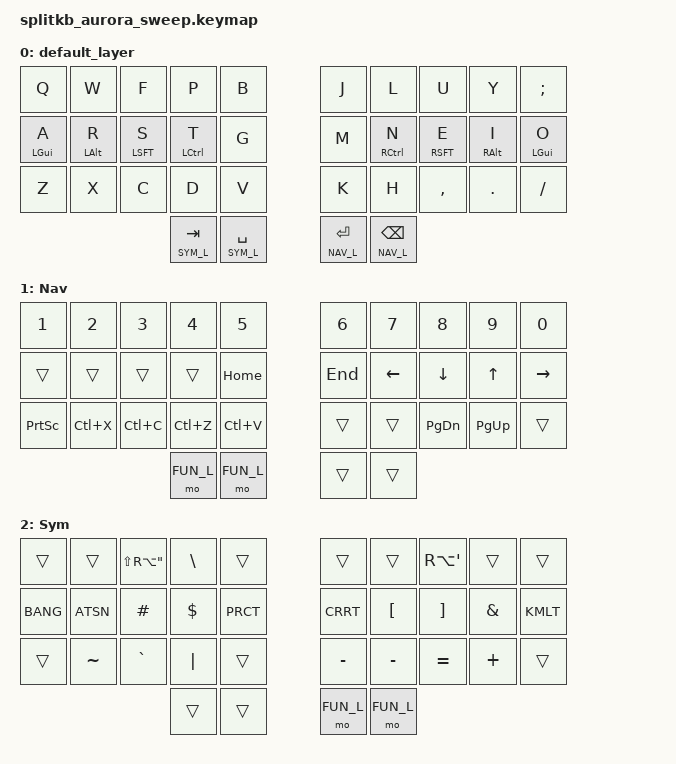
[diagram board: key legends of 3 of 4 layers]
/*
 * Copyright (c) 2022 The ZMK Contributors
 *
 * SPDX-License-Identifier: MIT
 */

#include <behaviors.dtsi>
#include <dt-bindings/zmk/keys.h>
#include <dt-bindings/zmk/bt.h>

#define DEF_L 0
#define NAV_L 1
#define SYM_L 2
#define FUN_L 3

// Using layer taps on thumbs, having quick tap as well helps w/ repeating space/backspace
&lt { quick_tap_ms = <200>; };


/ {
 behaviors {
        hm: homerow_mods {
            compatible = "zmk,behavior-hold-tap";
            #binding-cells = <2>;
            tapping_term_ms = <225>;
            flavor = "tap-preferred";
            bindings = <&kp>, <&kp>;
        };
    };

    macros {

        ZMK_MACRO(arrow,
            wait-ms = <30>;
            tap-ms = <40>;
            bindings = <&kp MINUS &kp LS(DOT)>;
        )

        ZMK_MACRO(eql_arrow,
            wait-ms = <30>;
            tap-ms = <40>;
            bindings = <&kp EQL &kp LS(DOT)>;
        )
    };

    combos {
        compatible = "zmk,combos";
        combo_esc {
            timeout-ms = <50>;
            key-positions = <0 1>;
            bindings = <&kp ESC>;
        };
        combo_capsword {
            timeout-ms = <50>;
            key-positions = <12 17>;
            bindings = <&caps_word>;
        };
        combo_eql_arrow {
            timeout-ms = <50>;
            key-positions = <3 4>;
            layers = <0 1 2 4>;
            bindings = <&eql_arrow>;
        };

        combo_arrow {
            timeout-ms = <50>;
            key-positions = <13 14>;
            layers = <0 1 2 4>;
            bindings = <&arrow>;
        };

         combo_tab {
            timeout-ms = <50>;
            key-positions = <11 12>;
            layers = <0 1 2 4>;
            bindings = <&kp TAB>;
        };

        combo_LPRN {
            timeout-ms = <50>;
            key-positions = <2 12>;
            layers = <0 1 2 4>;
            bindings = <&kp LPRN>;
        };

        combo_LBRC {
            timeout-ms = <50>;
            key-positions = <3 13>;
            layers = <0 1 2 4>;
            bindings = <&kp LBRC>;
        };

        combo_LBKT {
            timeout-ms = <50>;
            key-positions = <1 11>;
            layers = <0 1 2 4>;
            bindings = <&kp LBKT>;
        };

        combo_RPRN {
            timeout-ms = <50>;
            key-positions = <7 17>;
            layers = <0 1 2 4>;
            bindings = <&kp RPRN>;
        };

        combo_RBRC {
            timeout-ms = <50>;
            key-positions = <6 16>;
            layers = <0 1 2 4>;
            bindings = <&kp RBRC>;
        };

        combo_RBKT {
            timeout-ms = <50>;
            key-positions = <8 18>;
            layers = <0 1 2 4>;
            bindings = <&kp RBKT>;
        };

        combo_UNDER {
            timeout-ms = <50>;
            key-positions = <15 25>;
            layers = <0 1 2 4>;
            bindings = <&kp UNDER>;
        };

         combo_del {
            timeout-ms = <50>;
            key-positions = <8 9>;
            layers = <0 1 2 4>;
            bindings = <&kp DEL>;
        };

        combo_ae {
            timeout-ms = <50>;
            key-positions = <17 18>;
            layers = <0 1 2 4>;
            bindings = <&kp RA(Q)>;
        };

        combo_oe {
            timeout-ms = <50>;
            key-positions = <27 28>;
            layers = <0 1 2 4>;
            bindings = <&kp RA(P)>;
        };

        combo_a {
            timeout-ms = <50>;
            key-positions = <7 8>;
            layers = <0 1 2 4>;
            bindings = <&kp RA(W)>;
        };

        combo_to_default {
            timeout-ms = <50>;
            key-positions = <31 32>;
            bindings = <&to 0>;
        };

        combo_delword {
            timeout-ms = <50>;
            key-positions = <26 28>;
            layers = <0 1 2 4>;
            bindings = <&kp LC(BKSP)>;
        };

        combo_bspc {
            timeout-ms = <50>;
            key-positions = <26 27>;
            layers = <0 1 2 4>;
            bindings = <&kp LC(BKSP)>;
        };

        combo_eql {
            timeout-ms = <50>;
            key-positions = <6 7>;
            layers = <0 1 2 4>;
            bindings = <&kp EQL>;
        };

        combo_minus {
            timeout-ms = <50>;
            key-positions = <2 3>;
            layers = <0 1 2 4>;
            bindings = <&kp MINUS>;
        };

        combo_plus {
            timeout-ms = <50>;
            key-positions = <22 23>;
            layers = <0 1 2 4>;
            bindings = <&kp PLUS>;
        };
    };

        keymap {
                compatible = "zmk,keymap";

            default_layer {
        bindings = <

        &kp Q      &kp W      &kp F      &kp P      &kp B         &kp J   &kp L      &kp U      &kp Y      &kp SEMI
        &hm LGUI A &hm LALT R &hm LSFT S &hm LCTL T &kp G         &kp M   &hm RCTL N &hm RSFT E &hm RALT I &hm LGUI O
        &kp Z      &kp X      &kp C      &kp D      &kp V         &kp K   &kp H      &kp CMMA   &kp DOT    &kp SLASH
                        &lt SYM_L TAB    &lt SYM_L SPC                    &lt NAV_L RET   &lt NAV_L BKSP
        >;
        };

            nav_layer {
            display-name = "Nav";
        bindings = <

        &kp NUM_1  &kp NUM_2  &kp NUM_3  &kp NUM_4  &kp NUM_5                   &kp NUM_6  &kp NUM_7  &kp NUM_8  &kp NUM_9  &kp NUM_0
        &trans     &trans     &trans     &trans     &kp HOME                    &kp END    &kp LEFT   &kp DOWN   &kp UP     &kp RIGHT
        &kp PSCRN  &kp LC(X)  &kp LC(C)  &kp LC(Z)  &kp LC(V)                   &trans     &trans     &kp PG_DN  &kp PG_UP  &trans
                              &mo FUN_L  &mo FUN_L                                         &trans     &trans
        >;
        };

            sym_layer {
            display-name = "Sym";
        bindings = <

        &trans    &trans   &kp LS(RA(DQT))  &kp BACKSLASH  &trans               &trans    &trans    &kp RA(SQT) &trans   &trans
        &kp BANG  &kp ATSN   &kp HASH       &kp DLLR       &kp PRCT             &kp CRRT  &kp LBKT  &kp RBKT    &kp AMPS &kp KMLT
        &trans    &kp TILDE  &kp GRAVE      &kp PIPE       &trans               &kp MINUS &kp MINUS &kp EQL     &kp PLUS &trans
                             &trans  &trans                                               &mo FUN_L &mo FUN_L
        >;
        };

             func_layer {
            display-name = "Func";
        bindings = <
        &kp F1     &kp F2     &kp F3     &kp F4       &kp F5           &kp F6       &kp F7      &kp F8       &kp F9       &kp F10
        &trans     &trans     &trans     &trans       &trans           &trans       &trans      &trans       &trans       &kp F11
        &kp PSCRN  &bt BT_NXT &bt BT_PRV &bt BT_SEL 0 &bt BT_SEL 1     &bt BT_SEL 2 &bt BT_CLR  &kp K_VOL_UP &kp K_VOL_DN &kp F12
                              &trans     &trans                                     &trans   
        >;
        };
    };
};
